# ATtiny13 device description
Architecture: AVR8; Family: tinyAVR
Programming and debug interfaces: ISP, HVSP, debugWIRE
Registers are 8-bit, access not given, no defined reset value unless marked. A register's access mark holds for its fields unless they carry their own. Offsets are from the block's base; lines under a group give offsets from that group; [hi:lo] are bit positions; {n}, {i} and the like mark numbered series; 'fields as' and 'values as' point back to an identical list; <NAME> marks a mode.

## Ordering variants
ATtiny13V-10PU: PDIP8, pinout PDIP8_SOIC8, up to 10 MHz, -40 to 85 C, 1.8 to 5.5 V
ATtiny13V-10SU, ATtiny13V-10SSU: SOIC8, pinout PDIP8_SOIC8, up to 10 MHz, -40 to 85 C, 1.8 to 5.5 V
ATtiny13V-10MU: MLF20, up to 10 MHz, -40 to 85 C, 1.8 to 5.5 V
ATtiny13V-10MMU: MLF10, up to 10 MHz, -40 to 85 C, 1.8 to 5.5 V
ATtiny13-20PU: PDIP8, pinout PDIP8_SOIC8, up to 20 MHz, -40 to 85 C, 1.8 to 5.5 V
ATtiny13-20SU, ATtiny13-20SSU: SOIC8, pinout PDIP8_SOIC8, up to 20 MHz, -40 to 85 C, 1.8 to 5.5 V
ATtiny13-20MU: MLF20, up to 20 MHz, -40 to 85 C, 1.8 to 5.5 V
ATtiny13-20MMU: MLF10, up to 20 MHz, -40 to 85 C, 1.8 to 5.5 V

## Memory
prog space: start 0x0000 size 0x0400, little endian
  0x0000 FLASH size 0x0400 flash, rw, executable, page 0x20
signatures space: start 0 size 3, little endian
  0 SIGNATURES size 3 signatures, ro
fuses space: start 0 size 0x0002, little endian
  0 FUSES size 0x0002 fuses, rw
lockbits space: start 0 size 0x0001, little endian
  0 LOCKBITS size 0x0001 lockbits, rw
data space: start 0x0000 size 0x00a0, little endian
  0x0000 REGISTERS size 0x0020 regs
  0x0020 MAPPED_IO size 0x0040 io
  0x0060 IRAM size 0x0040 ram
eeprom space: start 0x0000 size 0x0040, little endian
  0x0000 EEPROM size 0x0040 eeprom, rw, page 0x04
io space: start 0x00 size 0x40, little endian
osccal space: start 0 size 2, little endian
  0 OSCCAL size 2 osccal, ro

## Peripheral instances (address, pins/pin function, parameters)
ADC at 0x00 — Analog-to-Digital Converter
  pins: ADC0 PA0; ADC1 PA1; ADC2 PA2; ADC3 PA3
AC at 0x00 — Analog Comparator
  pins: AIN1 PB1; AIN0 PB0
EEPROM at 0x00
CPU at 0x00 — CPU Registers
  parameters: CORE_VERSION=V2, NEW_INSTRUCTIONS=lpm rd,z+
PORTB at 0x00 — I/O Port
  pins: P0 PB0; P1 PB1; P2 PB2; P3 PB3; P4 PB4; P5 PB5
EXINT at 0x00 — External Interrupts
  pins: PCINT5 PB5; PCINT4 PB4; PCINT3 PB3; PCINT2 PB2; PCINT1 PB1; INT PB1; PCINT0 PB0
TC0 at 0x00 — Timer/Counter, 8-bit
  pins: T PB2; OCB PB1; OCA PB0
WDT at 0x00 — Watchdog Timer
FUSE at 0 in fuses — Fuses
LOCKBIT at 0 in lockbits — Lockbits

## Interrupts
0 RESET — External Reset, Power-on Reset and Watchdog Reset
1 INT0 — External Interrupt 0
2 PCINT0 — External Interrupt Request 0
3 TIM0_OVF — Timer/Counter0 Overflow
4 EE_RDY — EEPROM Ready
5 ANA_COMP — Analog Comparator
6 TIM0_COMPA — Timer/Counter Compare Match A
7 TIM0_COMPB — Timer/Counter Compare Match B
8 WDT — Watchdog Time-out
9 ADC — ADC Conversion Complete

## Properties
SIGNATURES: JTAGID=0x9007, SIGNATURE0=0x1e, SIGNATURE1=0x90, SIGNATURE2=0x07
OCD: OCD_REVISION=0, OCD_DATAREG=0x2e, PROGBASE=0x0000

## Pinouts (pin number, pad)
PDIP8_SOIC8: 1 PB5, 2 PB3, 3 PB4, 4 GND, 5 PB0, 6 PB1, 7 PB2, 8 VCC
MLF20: 1 PB5, 2 PB3, 5 PB4, 11 PB0, 12 PB1, 14 PB2, 15 VCC, 21 GND
MLF10: 1 PB5, 2 PB3, 4 PB4, 5 GND, 6 PB0, 7 PB1, 9 PB2, 10 VCC

## FUSE — Fuses
Instances: FUSE 0 in fuses
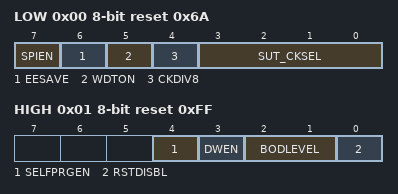
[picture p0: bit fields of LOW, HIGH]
0x00 LOW reset 0x6A
  [7] SPIEN — Serial program downloading (SPI) enabled
  [6] EESAVE — Preserve EEPROM through the Chip Erase cycle
  [5] WDTON — Watch-dog Timer always on
  [4] CKDIV8 — Divide clock by 8 internally
  [3:0] SUT_CKSEL — Select Clock Source
    0=EXTCLK_14CK_0MS (Ext. Clock; Start-up time: 14 CK + 0 ms); 4=EXTCLK_14CK_4MS (Ext. Clock; Start-up time: 14 CK + 4 ms); 8=EXTCLK_14CK_64MS (Ext. Clock; Start-up time: 14 CK + 64 ms); 1=INTRCOSC_4MHZ8_14CK_0MS (Int. RC Osc. 4.8 MHz; Start-up time: 14 CK + 0 ms); 5=INTRCOSC_4MHZ8_14CK_4MS (Int. RC Osc. 4.8 MHz; Start-up time: 14 CK + 4 ms); 9=INTRCOSC_4MHZ8_14CK_64MS (Int. RC Osc. 4.8 MHz; Start-up time: 14 CK + 64 ms); 2=INTRCOSC_9MHZ6_14CK_0MS (Int. RC Osc. 9.6 MHz; Start-up time: 14 CK + 0 ms); 6=INTRCOSC_9MHZ6_14CK_4MS (Int. RC Osc. 9.6 MHz; Start-up time: 14 CK + 4 ms); 10=INTRCOSC_9MHZ6_14CK_64MS (Int. RC Osc. 9.6 MHz; Start-up time: 14 CK + 64 ms); 3=INTRCOSC_128KHZ_14CK_0MS (Int. RC Osc. 128 kHz; Start-up time: 14 CK + 0 ms); 7=INTRCOSC_128KHZ_14CK_4MS (Int. RC Osc. 128 kHz; Start-up time: 14 CK + 4 ms); 11=INTRCOSC_128KHZ_14CK_64MS (Int. RC Osc. 128 kHz; Start-up time: 14 CK + 64 ms)
0x01 HIGH reset 0xFF
  [4] SELFPRGEN — Self Programming enable
  [3] DWEN — Debug Wire enable
  [2:1] BODLEVEL — Enable BOD and select level
    0=4V3 (Brown-out detection at VCC=4.3 V); 1=2V7 (Brown-out detection at VCC=2.7 V); 2=1V8 (Brown-out detection at VCC=1.8 V); 3=DISABLED (Brown-out detection disabled)
  [0] RSTDISBL — Reset Disabled (Enable PB5 as i/o pin)
